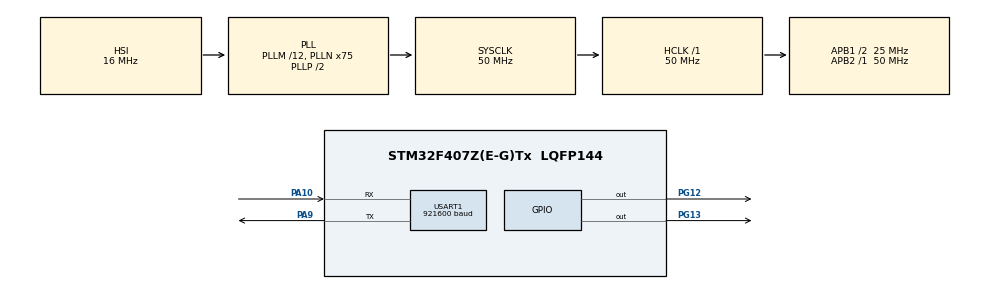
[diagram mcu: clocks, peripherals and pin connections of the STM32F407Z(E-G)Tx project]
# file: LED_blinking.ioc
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Mcu.Family=STM32F4
Mcu.Name=STM32F407Z(E-G)Tx
Mcu.Package=LQFP144
NVIC.PriorityGroup=NVIC_PRIORITYGROUP_4
NVIC.TIM6_DAC_IRQn=true\:0\:0\:false\:false\:true\:true\:true\:true
PA10.Mode=Asynchronous
PA10.Signal=USART1_RX
PA9.Mode=Asynchronous
PA9.Signal=USART1_TX
PG12.Signal=GPIO_Output
PG13.Signal=GPIO_Output
ProjectManager.HeapSize=0x200
ProjectManager.StackSize=0x400
ProjectManager.TargetToolchain=EWARM V8.50
RCC.48MHZClocksFreq_Value=25000000
RCC.AHBFreq_Value=50000000
RCC.APB1CLKDivider=RCC_HCLK_DIV2
RCC.APB1Freq_Value=25000000
RCC.APB1TimFreq_Value=50000000
RCC.APB2Freq_Value=50000000
RCC.APB2TimFreq_Value=50000000
RCC.CortexFreq_Value=50000000
RCC.HCLKFreq_Value=50000000
RCC.HSE_VALUE=25000000
RCC.HSI_VALUE=16000000
RCC.LSE_VALUE=32768
RCC.PLLM=12
RCC.PLLN=75
RCC.SYSCLKFreq_VALUE=50000000
RCC.SYSCLKSource=RCC_SYSCLKSOURCE_PLLCLK
RCC.VCOOutputFreq_Value=100000000
TIM6.Period=9999
TIM6.Prescaler=499
USART1.BaudRate=921600
USART1.VirtualMode=VM_ASYNC
VP_TIM6_VS_ClockSourceINT.Mode=Enable_Timer
board=custom

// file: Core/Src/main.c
/* USER CODE BEGIN Header */
/**
  ******************************************************************************
  * @file           : main.c
  * @brief          : Main program body
  ******************************************************************************
  * @attention
  *
  * Copyright (c) 2024 STMicroelectronics.
  * All rights reserved.
  *
  * This software is licensed under terms that can be found in the LICENSE file
  * in the root directory of this software component.
  * If no LICENSE file comes with this software, it is provided AS-IS.
  *
  ******************************************************************************
  */
/* USER CODE END Header */
#include "main.h"
#include <stdio.h>
#include <stdbool.h>

TIM_HandleTypeDef htim6;

UART_HandleTypeDef huart1;

bool gToggle;
uint8_t g1secCnt, gSec;

void SystemClock_Config(void);
static void MX_GPIO_Init(void);
static void MX_USART1_UART_Init(void);
static void MX_TIM6_Init(void);

int fputc(int ch, FILE *f)
{
    /* Place your implementation of fputc here */
    /* e.g. write a character to the EVAL_COM1 and Loop until the end of transmission */
    if( ch == '\n' ){
            ch = '\r';
    HAL_UART_Transmit( &huart1, (uint8_t *)&ch, 1, 0xFFFF );
    ch = '\n';
    }

    HAL_UART_Transmit( &huart1, (uint8_t *)&ch, 1, 0xFFFF );

    return ch;
}

void HAL_TIM_PeriodElapsedCallback(TIM_HandleTypeDef *htim)
{
  gToggle = !gToggle;

  if (g1secCnt >= 10) {
    g1secCnt = 0;
    gSec++;
  } else g1secCnt++;

  if(htim->Instance == TIM6)
  {
      HAL_GPIO_WritePin(GPIOG, GPIO_PIN_12, gToggle);
  }
}

int main(void)
{
  /* MCU Configuration--------------------------------------------------------*/

  /* Reset of all peripherals, Initializes the Flash interface and the Systick. */
  HAL_Init();

  /* Configure the system clock */
  SystemClock_Config();

  __enable_irq();
  /* Initialize all configured peripherals */
  MX_GPIO_Init();
  MX_USART1_UART_Init();
  MX_TIM6_Init();

  HAL_TIM_Base_Start_IT(&htim6);

  /* USER CODE BEGIN 2 */
  printf("******************************\r\n\r\n");
  printf("USART DBG TEST!\r\n\r\n");
  printf("******************************\r\n\r\n");
  /* USER CODE END 2 */

  /* Infinite loop */

  while (1)
  {
    //HAL_GPIO_WritePin(GPIOG, GPIO_PIN_12, GPIO_PIN_RESET);
    //HAL_Delay(100);
    //HAL_GPIO_WritePin(GPIOG, GPIO_PIN_12, GPIO_PIN_SET);
    //HAL_Delay(100);

    //printf("CNT: %d00ms\r\n", g1secCnt);

    if (g1secCnt >= 10)
      printf("CNT: %d Sec\r\n", gSec);

    //HAL_GPIO_TogglePin(GPIOG, GPIO_PIN_13);
    //HAL_Delay(100);
  }

}

void SystemClock_Config(void)
{
  RCC_OscInitTypeDef RCC_OscInitStruct = {0};
  RCC_ClkInitTypeDef RCC_ClkInitStruct = {0};

  /** Configure the main internal regulator output voltage
  */
  __HAL_RCC_PWR_CLK_ENABLE();
  __HAL_PWR_VOLTAGESCALING_CONFIG(PWR_REGULATOR_VOLTAGE_SCALE1);

  /** Initializes the RCC Oscillators according to the specified parameters
  * in the RCC_OscInitTypeDef structure.
  */
  RCC_OscInitStruct.OscillatorType = RCC_OSCILLATORTYPE_HSI;
  RCC_OscInitStruct.HSIState = RCC_HSI_ON;
  RCC_OscInitStruct.HSICalibrationValue = RCC_HSICALIBRATION_DEFAULT;
  RCC_OscInitStruct.PLL.PLLState = RCC_PLL_ON;
  RCC_OscInitStruct.PLL.PLLSource = RCC_PLLSOURCE_HSI;
  RCC_OscInitStruct.PLL.PLLM = 12;
  RCC_OscInitStruct.PLL.PLLN = 75;
  RCC_OscInitStruct.PLL.PLLP = RCC_PLLP_DIV2;
  RCC_OscInitStruct.PLL.PLLQ = 4;
  if (HAL_RCC_OscConfig(&RCC_OscInitStruct) != HAL_OK)
  {
    Error_Handler();
  }

  /** Initializes the CPU, AHB and APB buses clocks
  */
  RCC_ClkInitStruct.ClockType = RCC_CLOCKTYPE_HCLK|RCC_CLOCKTYPE_SYSCLK
                              |RCC_CLOCKTYPE_PCLK1|RCC_CLOCKTYPE_PCLK2;
  RCC_ClkInitStruct.SYSCLKSource = RCC_SYSCLKSOURCE_PLLCLK;
  RCC_ClkInitStruct.AHBCLKDivider = RCC_SYSCLK_DIV1;
  RCC_ClkInitStruct.APB1CLKDivider = RCC_HCLK_DIV2;
  RCC_ClkInitStruct.APB2CLKDivider = RCC_HCLK_DIV1;

  if (HAL_RCC_ClockConfig(&RCC_ClkInitStruct, FLASH_LATENCY_1) != HAL_OK)
  {
    Error_Handler();
  }
}

static void MX_TIM6_Init(void)
{

  TIM_MasterConfigTypeDef sMasterConfig = {0};

  htim6.Instance = TIM6;
  htim6.Init.Prescaler = 499;
  htim6.Init.CounterMode = TIM_COUNTERMODE_UP;
  htim6.Init.Period = 9999;
  htim6.Init.AutoReloadPreload = TIM_AUTORELOAD_PRELOAD_DISABLE;
  if (HAL_TIM_Base_Init(&htim6) != HAL_OK)
  {
    Error_Handler();
  }
  sMasterConfig.MasterOutputTrigger = TIM_TRGO_RESET;
  sMasterConfig.MasterSlaveMode = TIM_MASTERSLAVEMODE_DISABLE;
  if (HAL_TIMEx_MasterConfigSynchronization(&htim6, &sMasterConfig) != HAL_OK)
  {
    Error_Handler();
  }

}

static void MX_USART1_UART_Init(void)
{

  huart1.Instance = USART1;
  huart1.Init.BaudRate = 921600;
  huart1.Init.WordLength = UART_WORDLENGTH_8B;
  huart1.Init.StopBits = UART_STOPBITS_1;
  huart1.Init.Parity = UART_PARITY_NONE;
  huart1.Init.Mode = UART_MODE_TX_RX;
  huart1.Init.HwFlowCtl = UART_HWCONTROL_NONE;
  huart1.Init.OverSampling = UART_OVERSAMPLING_16;
  if (HAL_UART_Init(&huart1) != HAL_OK)
  {
    Error_Handler();
  }

}

static void MX_GPIO_Init(void)
{
  GPIO_InitTypeDef GPIO_InitStruct = {0};

  /* GPIO Ports Clock Enable */
  __HAL_RCC_GPIOA_CLK_ENABLE();
  __HAL_RCC_GPIOG_CLK_ENABLE();

  /*Configure GPIO pin Output Level */
  HAL_GPIO_WritePin(GPIOG, GPIO_PIN_12|GPIO_PIN_13, GPIO_PIN_RESET);

  /*Configure GPIO pins : PG12 PG13 */
  GPIO_InitStruct.Pin = GPIO_PIN_12|GPIO_PIN_13;
  GPIO_InitStruct.Mode = GPIO_MODE_OUTPUT_PP;
  GPIO_InitStruct.Pull = GPIO_NOPULL;
  GPIO_InitStruct.Speed = GPIO_SPEED_FREQ_LOW;
  HAL_GPIO_Init(GPIOG, &GPIO_InitStruct);

}

void Error_Handler(void)
{
  __disable_irq();
  while (1)
  {
  }
}
